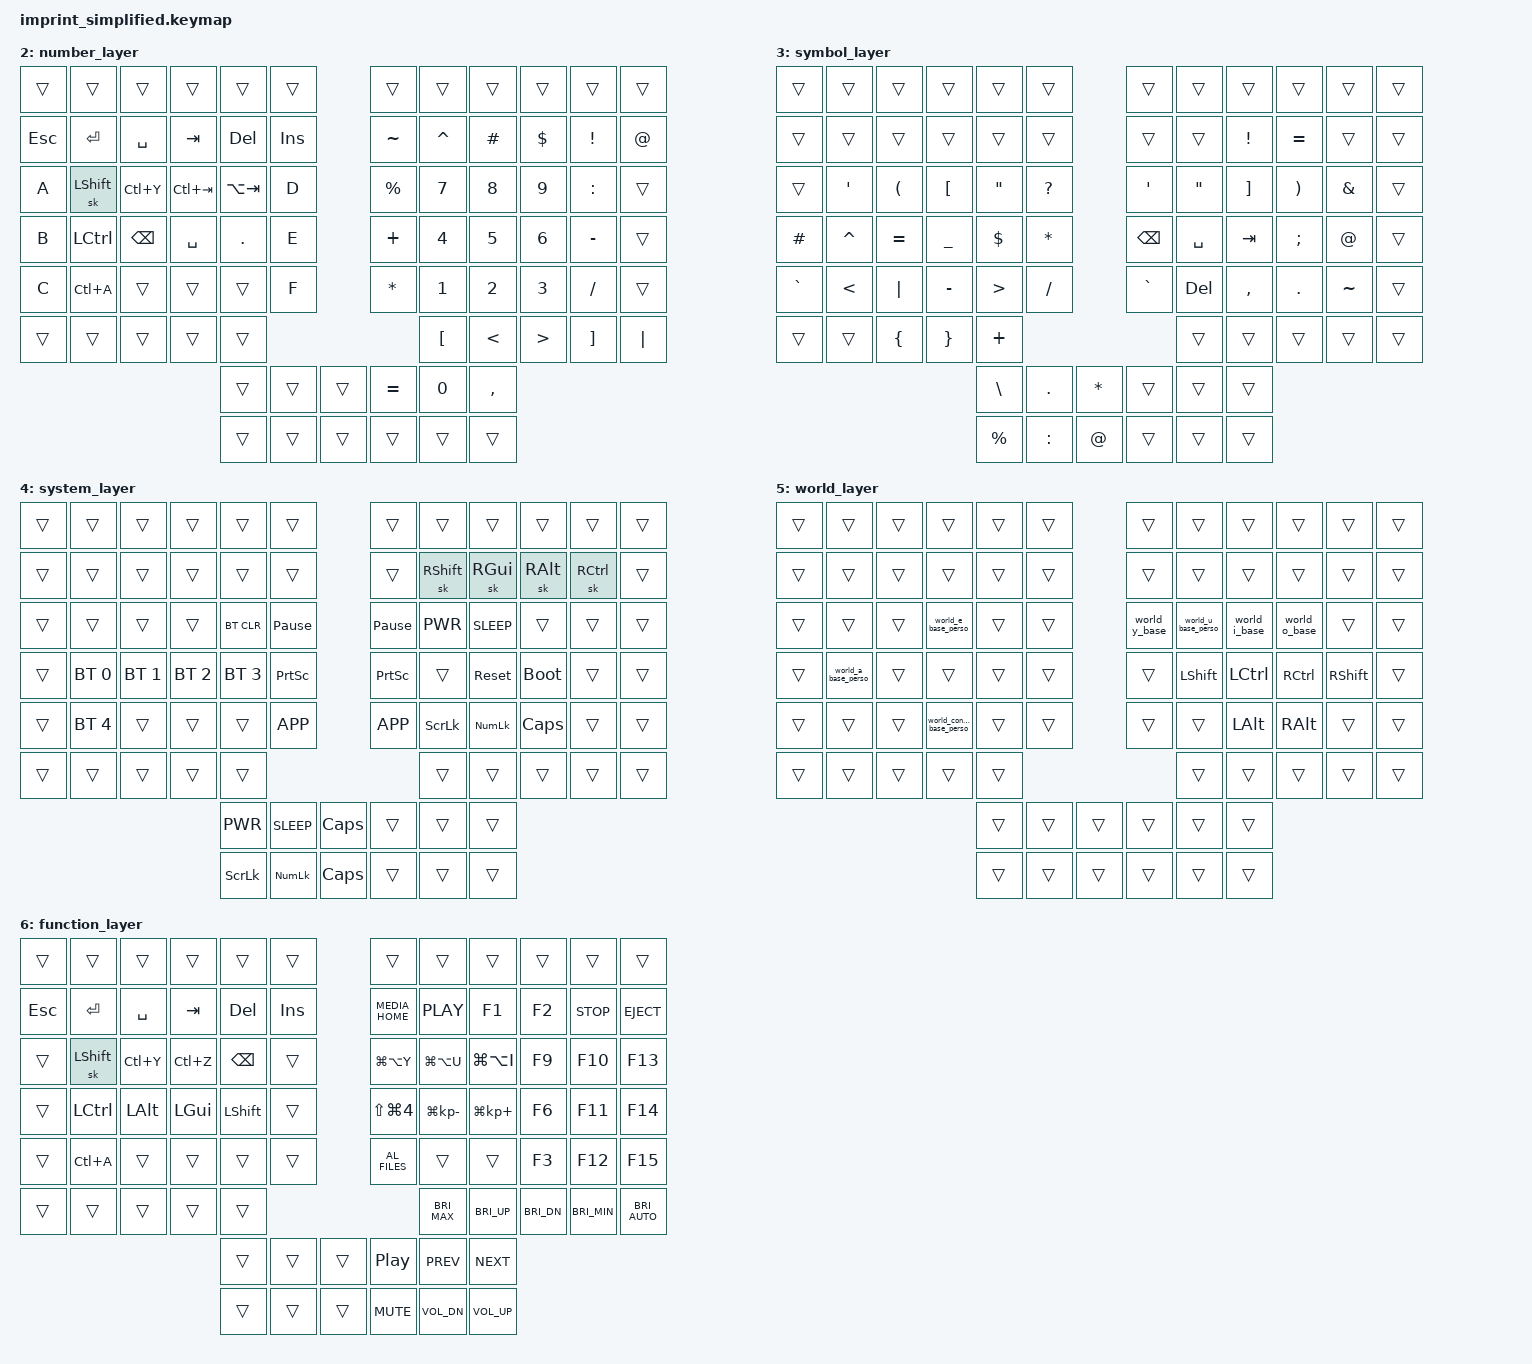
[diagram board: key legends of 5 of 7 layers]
#include <behaviors.dtsi>
#include <dt-bindings/zmk/keys.h>
#include <dt-bindings/zmk/bt.h>

/ {
    chosen { zmk,matrix-transform = &imprint_function_row_full_bottom_row; };

    behaviors {
        // Simplified mod-tap behaviors (macOS order: CTRL/ALT/GUI/SHIFT)
        lmt: left_mod_tap {
            compatible = "zmk,behavior-hold-tap";
            #binding-cells = <2>;
            flavor = "tap-preferred";
            tapping-term-ms = <200>;
            quick-tap-ms = <150>;
            bindings = <&kp>, <&kp>;
        };
        
        rmt: right_mod_tap {
            compatible = "zmk,behavior-hold-tap";
            #binding-cells = <2>;
            flavor = "tap-preferred";
            tapping-term-ms = <200>;
            quick-tap-ms = <150>;
            bindings = <&kp>, <&kp>;
        };

        // World character behaviors (système complet basé sur Glove80)
        world_a_base_perso: world_a_base_perso {
            compatible = "zmk,behavior-mod-morph";
            #binding-cells = <0>;
            bindings = <&kp RA(GRAVE)>, <&world_a_alt>;  // à -> autres variants
            mods = <(MOD_LALT|MOD_RALT|MOD_LCTL|MOD_RCTL|MOD_RSFT)>;
        };

        world_a_alt: world_a_alt {
            compatible = "zmk,behavior-mod-morph";
            #binding-cells = <0>;
            bindings = <&kp RA(A)>, <&kp RA(LS(A))>;  // á -> Á
            mods = <(MOD_LSFT|MOD_RSFT)>;
        };

        world_e_base_perso: world_e_base_perso {
            compatible = "zmk,behavior-mod-morph";
            #binding-cells = <0>;
            bindings = <&kp RA(GRAVE)>, <&world_e_alt>;  // è -> autres variants
            mods = <(MOD_RALT|MOD_LCTL|MOD_RCTL|MOD_RSFT)>;
        };

        world_e_alt: world_e_alt {
            compatible = "zmk,behavior-mod-morph";
            #binding-cells = <0>;
            bindings = <&kp RA(E)>, <&kp RA(LS(E))>;  // é -> É
            mods = <(MOD_LSFT|MOD_RSFT)>;
        };

        world_i_base: world_i_base {
            compatible = "zmk,behavior-mod-morph";
            #binding-cells = <0>;
            bindings = <&kp RA(I)>, <&world_i_ctrl>;  // í -> autres variants
            mods = <(MOD_LCTL|MOD_RCTL|MOD_RSFT)>;
        };

        world_i_ctrl: world_i_ctrl {
            compatible = "zmk,behavior-mod-morph";
            #binding-cells = <0>;
            bindings = <&kp RA(LS(U))>, <&kp RA(LS(I))>;  // î -> Î
            mods = <(MOD_LSFT|MOD_RSFT)>;
        };

        world_o_base: world_o_base {
            compatible = "zmk,behavior-mod-morph";
            #binding-cells = <0>;
            bindings = <&kp RA(O)>, <&world_o_alt>;  // ó -> autres variants
            mods = <(MOD_LALT|MOD_RALT|MOD_LCTL|MOD_RCTL|MOD_RSFT)>;
        };

        world_o_alt: world_o_alt {
            compatible = "zmk,behavior-mod-morph";
            #binding-cells = <0>;
            bindings = <&kp RA(LS(I))>, <&kp RA(LS(O))>;  // ô -> Ô
            mods = <(MOD_LSFT|MOD_RSFT)>;
        };

        world_u_base_perso: world_u_base_perso {
            compatible = "zmk,behavior-mod-morph";
            #binding-cells = <0>;
            bindings = <&kp RA(GRAVE)>, <&world_u_ctrl>;  // ù -> autres variants
            mods = <(MOD_LCTL|MOD_RCTL|MOD_RSFT)>;
        };

        world_u_ctrl: world_u_ctrl {
            compatible = "zmk,behavior-mod-morph";
            #binding-cells = <0>;
            bindings = <&kp RA(LS(I))>, <&kp RA(LS(U))>;  // û -> Û
            mods = <(MOD_LSFT|MOD_RSFT)>;
        };

        world_y_base: world_y_base {
            compatible = "zmk,behavior-mod-morph";
            #binding-cells = <0>;
            bindings = <&kp RA(Y)>, <&kp RA(LS(U))>;  // ý -> ÿ
            mods = <(MOD_LCTL)>;
        };

        world_consonants_base_perso: world_consonants_base_perso {
            compatible = "zmk,behavior-mod-morph";
            #binding-cells = <0>;
            bindings = <&kp RA(C)>, <&kp RA(LS(C))>;  // ç -> Ç
            mods = <(MOD_LALT|MOD_RALT|MOD_LCTL|MOD_RCTL|MOD_RSFT)>;
        };

        // Behavior pour é/É (comme dans votre config Glove80)
        world_e_acute: world_e_acute {
            compatible = "zmk,behavior-mod-morph";
            #binding-cells = <0>;
            bindings = <&kp RA(E)>, <&kp RA(LS(E))>;  // é -> É
            mods = <(MOD_LSFT|MOD_RSFT)>;
        };

        // Layer tap behaviors
        lt_cursor: layer_tap_cursor {
            compatible = "zmk,behavior-hold-tap";
            #binding-cells = <2>;
            flavor = "tap-preferred";
            tapping-term-ms = <200>;
            quick-tap-ms = <150>;
            bindings = <&mo>, <&kp>;
        };

        lt_number: layer_tap_number {
            compatible = "zmk,behavior-hold-tap";
            #binding-cells = <2>;
            flavor = "tap-preferred";
            tapping-term-ms = <200>;
            quick-tap-ms = <150>;
            bindings = <&mo>, <&kp>;
        };

        lt_symbol: layer_tap_symbol {
            compatible = "zmk,behavior-hold-tap";
            #binding-cells = <2>;
            flavor = "tap-preferred";
            tapping-term-ms = <200>;
            quick-tap-ms = <150>;
            bindings = <&mo>, <&kp>;
        };

        lt_system: layer_tap_system {
            compatible = "zmk,behavior-hold-tap";
            #binding-cells = <2>;
            flavor = "tap-preferred";
            tapping-term-ms = <200>;
            quick-tap-ms = <150>;
            bindings = <&mo>, <&kp>;
        };

        lt_world: layer_tap_world {
            compatible = "zmk,behavior-hold-tap";
            #binding-cells = <2>;
            flavor = "tap-preferred";
            tapping-term-ms = <200>;
            quick-tap-ms = <150>;
            bindings = <&mo>, <&kp>;
        };

        lt_function: layer_tap_function {
            compatible = "zmk,behavior-hold-tap";
            #binding-cells = <2>;
            flavor = "tap-preferred";
            tapping-term-ms = <200>;
            quick-tap-ms = <150>;
            bindings = <&mo>, <&kp>;
        };

        // Behaviors pour thumb cluster (comme Glove80)
        thumb: thumb_layer_access {
            compatible = "zmk,behavior-hold-tap";
            flavor = "balanced";
            tapping-term-ms = <200>;
            quick-tap-ms = <150>;
            #binding-cells = <2>;
            bindings = <&mo>, <&kp>;
        };

        space: thumb_layer_access_spacebar {
            compatible = "zmk,behavior-hold-tap";
            flavor = "balanced";
            tapping-term-ms = <200>;
            quick-tap-ms = <150>;
            #binding-cells = <2>;
            bindings = <&mo>, <&kp>;
        };
    };

    keymap {
        compatible = "zmk,keymap";

        // Layer 0: QWERTY (thumb cluster complet 6x6 comme Glove80)
        qwerty_layer {
            bindings = <
&kp ESC    &kp F1   &kp F2   &kp F3   &kp F4   &kp F5              &kp F6   &kp F7   &kp F8   &kp F9   &kp F10   &kp F11
&kp EQUAL  &kp N1   &kp N2   &world_e_acute   &kp SQT   &kp N5              &kp N6   &kp N7   &kp N8   &kp N9   &kp N0    &kp BSLH
&kp GRAVE  &kp Q    &kp W    &kp E    &kp R    &kp T               &kp Y    &kp U    &kp I    &kp O    &kp SEMI  &kp MINUS
&kp TAB    &lmt LCTRL A  &lmt LALT S  &lmt LGUI D  &lmt LSHFT F  &kp G     &kp H    &rmt RSHFT J  &rmt RGUI K  &rmt RALT L  &rmt RCTRL P  &kp SQT
&kp LSHFT  &kp Z    &kp X    &kp C    &kp V    &kp B               &kp N    &kp M    &kp COMMA &kp DOT  &kp FSLH  &kp RSHFT
&trans     &kp GRAVE &kp UP   &kp DOWN &kp LSHFT                           &trans   &kp LBKT  &kp RBKT &kp BSLH  &trans
                                     &thumb 6 ESC   &thumb 1 BACKSPACE &thumb 2 DELETE    &thumb 4 INSERT  &space 5 ENTER  &space 3 SPACE
                                     &kp LS(LC(LA(LGUI)))  &kp CAPS_WORD    &mo 1       &kp CAPS_WORD  &space 2 TAB     &mo 1
            >;
        };

        // Layer 1: Cursor/Navigation
        cursor_layer {
            bindings = <
&trans     &trans   &trans   &trans   &trans   &trans              &trans   &trans   &trans   &trans   &trans    &trans
&kp ESC    &kp RET  &kp SPACE &kp TAB  &kp DEL  &kp INS             &kp INS  &kp DEL  &kp TAB  &kp SPACE &kp RET  &kp ESC
&kp LC(K)  &kp LA(LG(E)) &kp LA(R) &kp LA(V) &kp LA(A) &kp LC(X)   &kp BSPC &kp SPACE &kp LC(Z) &kp LC(Y) &sk LSHFT &kp LC(K)
&kp LC(L)  &kp LCTRL &kp LALT &kp LGUI &kp LSHFT &kp LC(C)           &kp LEFT &kp DOWN &kp UP   &kp RIGHT &trans   &kp LC(L)
&kp LC(J)  &kp LC(A) &kp LA(T) &kp LA(LG(J)) &kp LA(LG(L)) &kp LC(V) &trans &kp F11  &kp PG_UP &kp PG_DN &kp END  &kp LC(J)
&kp LC(H)  &kp LC(F) &kp LC(Y) &kp LC(Z) &kp LC(G)                   &trans   &kp LC(F) &kp LS(F3) &kp F3   &trans    &kp LG(DOT)
                                     &trans   &trans   &trans         &trans   &trans   &trans
                                     &trans   &trans   &trans         &trans   &trans   &trans
            >;
        };

        // Layer 2: Number
        number_layer {
            bindings = <
&trans     &trans   &trans   &trans   &trans   &trans              &trans   &trans   &trans   &trans   &trans    &trans
&kp ESC    &kp RET  &kp SPACE &kp TAB  &kp DEL  &kp INS             &kp TILDE &kp CARET &kp HASH &kp DLLR &kp EXCL &kp AT
&kp A      &sk LSHFT &kp LC(Y) &kp LC(TAB) &kp LA(TAB) &kp D       &kp PRCNT &kp N7   &kp N8   &kp N9   &kp COLON &trans
&kp B      &kp LCTRL &kp BSPC &kp SPACE &kp DOT  &kp E              &kp PLUS  &kp N4   &kp N5   &kp N6   &kp MINUS &trans
&kp C      &kp LC(A) &trans   &trans   &trans   &kp F              &kp STAR  &kp N1   &kp N2   &kp N3   &kp FSLH  &trans
&trans     &trans   &trans   &trans   &trans                               &kp LBKT &kp LT   &kp GT   &kp RBKT  &kp PIPE
                                     &trans   &trans   &trans         &kp EQUAL &kp N0   &kp COMMA
                                     &trans   &trans   &trans         &trans   &trans   &trans
            >;
        };

        // Layer 3: Symbol
        symbol_layer {
            bindings = <
&trans     &trans   &trans   &trans   &trans   &trans              &trans   &trans   &trans   &trans   &trans    &trans
&trans     &trans   &trans   &trans   &trans   &trans              &trans   &trans   &kp EXCL &kp EQUAL &trans   &trans
&trans     &kp SQT  &kp LPAR &kp LBKT &kp DQT  &kp QMARK           &kp SQT  &kp DQT  &kp RBKT &kp RPAR &kp AMPS  &trans
&kp HASH   &kp CARET &kp EQUAL &kp UNDER &kp DLLR &kp STAR         &kp BSPC &kp SPACE &kp TAB  &kp SEMI &kp AT   &trans
&kp GRAVE  &kp LT   &kp PIPE &kp MINUS &kp GT   &kp FSLH           &kp GRAVE &kp DEL  &kp COMMA &kp DOT &kp TILDE &trans
&trans     &trans   &kp LBRC &kp RBRC &kp PLUS                             &trans   &trans   &trans   &trans    &trans
                                     &kp BSLH &kp DOT  &kp STAR       &trans   &trans   &trans
                                     &kp PRCNT &kp COLON &kp AT        &trans   &trans   &trans
            >;
        };

        // Layer 4: System
        system_layer {
            bindings = <
&trans     &trans   &trans   &trans   &trans   &trans              &trans   &trans   &trans   &trans   &trans    &trans
&trans     &trans   &trans   &trans   &trans   &trans              &trans   &sk RSHFT &sk RGUI &sk RALT &sk RCTRL &trans
&trans     &trans   &trans   &trans   &bt BT_CLR &kp PAUSE_BREAK   &kp PAUSE_BREAK &kp C_PWR &kp C_SLEEP &trans &trans &trans
&trans     &bt BT_SEL 0 &bt BT_SEL 1 &bt BT_SEL 2 &bt BT_SEL 3 &kp PSCRN &kp PSCRN &trans   &sys_reset &bootloader &trans &trans
&trans     &bt BT_SEL 4 &trans &trans &trans   &kp K_APP           &kp K_APP &kp SLCK &kp KP_NUM &kp CAPS &trans    &trans
&trans     &trans   &trans   &trans   &trans                               &trans   &trans   &trans   &trans    &trans
                                     &kp C_PWR &kp C_SLEEP &kp CAPS   &trans   &trans   &trans
                                     &kp SLCK &kp KP_NUM &kp CAPS      &trans   &trans   &trans
            >;
        };

        // Layer 5: World
        world_layer {
            bindings = <
&trans     &trans   &trans   &trans   &trans   &trans              &trans   &trans   &trans   &trans   &trans    &trans
&trans     &trans   &trans   &trans   &trans   &trans              &trans   &trans   &trans   &trans   &trans    &trans
&trans     &trans   &trans   &world_e_base_perso   &trans   &trans   &world_y_base   &world_u_base_perso   &world_i_base   &world_o_base   &trans    &trans
&trans     &world_a_base_perso    &trans   &trans   &trans   &trans              &trans   &kp LSHFT &kp LCTRL &kp RCTRL &kp RSHFT &trans
&trans     &trans   &trans   &world_consonants_base_perso   &trans   &trans              &trans   &trans   &kp LALT &kp RALT &trans    &trans
&trans     &trans   &trans   &trans   &trans                               &trans   &trans   &trans   &trans    &trans
                                     &trans   &trans   &trans         &trans   &trans   &trans
                                     &trans   &trans   &trans         &trans   &trans   &trans
            >;
        };

        // Layer 6: Function (basé sur layer_Function du Glove80)
        function_layer {
            bindings = <
&trans     &trans   &trans   &trans   &trans   &trans              &trans   &trans   &trans   &trans   &trans    &trans
&kp ESC    &kp RET  &kp SPACE &kp TAB  &kp DEL  &kp INS             &kp C_MEDIA_HOME &kp C_PLAY &kp F1   &kp F2   &kp C_STOP &kp C_EJECT
&trans     &sk LSHFT &kp LC(Y) &kp LC(Z) &kp BSPC &trans            &kp LG(LA(Y)) &kp LG(LA(U)) &kp LG(LA(I)) &kp F9 &kp F10 &kp F13
&trans     &kp LCTRL &kp LALT &kp LGUI &kp LSHFT &trans             &kp LS(LG(N4)) &kp LG(KP_MINUS) &kp LG(KP_PLUS) &kp F6 &kp F11 &kp F14
&trans     &kp LC(A) &trans   &trans   &trans   &trans              &kp C_AL_FILES &trans        &trans   &kp F3   &kp F12 &kp F15
&trans     &trans   &trans   &trans   &trans                               &kp C_BRI_MAX &kp C_BRI_UP &kp C_BRI_DN &kp C_BRI_MIN &kp C_BRI_AUTO
                                     &trans   &trans   &trans         &kp C_PP &kp C_PREV &kp C_NEXT
                                     &trans   &trans   &trans         &kp C_MUTE &kp C_VOL_DN &kp C_VOL_UP
            >;
        };
    };
};
